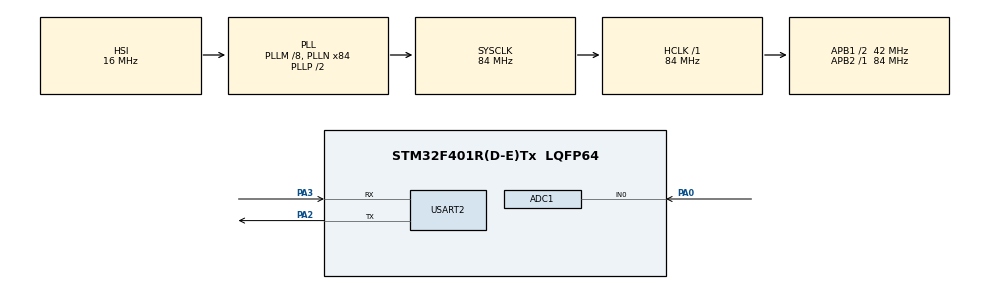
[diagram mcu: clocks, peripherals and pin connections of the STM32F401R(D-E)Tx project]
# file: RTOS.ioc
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ADC1.Channel-0\#ChannelRegularConversion=ADC_CHANNEL_0
ADC1.NbrOfConversionFlag=1
ADC1.Rank-0\#ChannelRegularConversion=1
ADC1.SamplingTime-0\#ChannelRegularConversion=ADC_SAMPLETIME_3CYCLES
ADC1.master=1
FREERTOS.Tasks01=defaultTask,0,128,StartDefaultTask,Default,NULL,Dynamic,NULL,NULL;ADCTask,0,128,StartADCTask,Default,NULL,Dynamic,NULL,NULL;UARTTask,0,128,StartUARTTask,Default,NULL,Dynamic,NULL,NULL
FREERTOS.configUSE_NEWLIB_REENTRANT=1
Mcu.Family=STM32F4
Mcu.Name=STM32F401R(D-E)Tx
Mcu.Package=LQFP64
NVIC.ADC_IRQn=true\:6\:0\:true\:false\:true\:true\:true\:true
NVIC.PriorityGroup=NVIC_PRIORITYGROUP_4
NVIC.TIM1_UP_TIM10_IRQn=true\:0\:0\:false\:false\:true\:false\:false\:true
NVIC.TIM3_IRQn=true\:5\:0\:false\:false\:true\:true\:true\:true
NVIC.TimeBase=TIM1_UP_TIM10_IRQn
NVIC.TimeBaseIP=TIM10
NVIC.USART2_IRQn=true\:7\:0\:true\:false\:true\:true\:true\:true
PA0-WKUP.Signal=ADCx_IN0
PA2.Mode=Asynchronous
PA2.Signal=USART2_TX
PA3.Mode=Asynchronous
PA3.Signal=USART2_RX
ProjectManager.HeapSize=0x3c00
ProjectManager.StackSize=0x3c00
ProjectManager.TargetToolchain=STM32CubeIDE
RCC.48MHZClocksFreq_Value=42000000
RCC.AHBFreq_Value=84000000
RCC.APB1CLKDivider=RCC_HCLK_DIV2
RCC.APB1Freq_Value=42000000
RCC.APB1TimFreq_Value=84000000
RCC.APB2Freq_Value=84000000
RCC.APB2TimFreq_Value=84000000
RCC.CortexFreq_Value=84000000
RCC.HCLKFreq_Value=84000000
RCC.HSE_VALUE=25000000
RCC.HSI_VALUE=16000000
RCC.LSE_VALUE=32768
RCC.PLLM=8
RCC.PLLN=84
RCC.SYSCLKFreq_VALUE=84000000
RCC.SYSCLKSource=RCC_SYSCLKSOURCE_PLLCLK
RCC.VCOOutputFreq_Value=168000000
SH.ADCx_IN0.0=ADC1_IN0,IN0
TIM3.AutoReloadPreload=TIM_AUTORELOAD_PRELOAD_ENABLE
TIM3.Period=1999
TIM3.Prescaler=42000
USART2.VirtualMode=VM_ASYNC
VP_FREERTOS_VS_CMSIS_V1.Mode=CMSIS_V1
VP_SYS_VS_tim10.Mode=TIM10
VP_TIM3_VS_ClockSourceINT.Mode=Internal
board=custom

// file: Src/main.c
/* USER CODE BEGIN Header */
/**
  ******************************************************************************
  * @file           : main.c
  * @brief          : Main program body
  ******************************************************************************
  * @attention
  *
  * <h2><center>&copy; Copyright (c) 2019 STMicroelectronics.
  * All rights reserved.</center></h2>
  *
  * This software component is licensed by ST under BSD 3-Clause license,
  * the "License"; You may not use this file except in compliance with the
  * License. You may obtain a copy of the License at:
  *                        opensource.org/licenses/BSD-3-Clause
  *
  ******************************************************************************
  */
/* USER CODE END Header */
#include "main.h"
#include "cmsis_os.h"

/* USER CODE BEGIN Includes */
#include <stdio.h>
#include <string.h>
/* USER CODE END Includes */

/* USER CODE BEGIN PD */
#define SIGNAL_TIM_INT 1
#define SIGNAL_ADC 2
#define SIGNAL_ADC_INT 4
#define SIGNAL_UART 8
#define SIGNAL_UART_INT 16
/* USER CODE END PD */

ADC_HandleTypeDef hadc1;

TIM_HandleTypeDef htim3;

UART_HandleTypeDef huart2;

osThreadId defaultTaskHandle;
osThreadId ADCTaskHandle;
osThreadId UARTTaskHandle;
/* USER CODE BEGIN PV */
uint8_t UARTBuf[16] = {'\0'};
/* USER CODE END PV */

void SystemClock_Config(void);
static void MX_GPIO_Init(void);
static void MX_ADC1_Init(void);
static void MX_TIM3_Init(void);
static void MX_USART2_UART_Init(void);
void StartDefaultTask(void const * argument);
void StartADCTask(void const * argument);
void StartUARTTask(void const * argument);

int main(void)
{

  /* MCU Configuration--------------------------------------------------------*/

  /* Reset of all peripherals, Initializes the Flash interface and the Systick. */
  HAL_Init();

  /* Configure the system clock */
  SystemClock_Config();

  /* Initialize all configured peripherals */
  MX_GPIO_Init();
  MX_ADC1_Init();
  MX_TIM3_Init();
  MX_USART2_UART_Init();

  /* Create the thread(s) */
  /* definition and creation of defaultTask */
  osThreadDef(defaultTask, StartDefaultTask, osPriorityNormal, 0, 128);
  defaultTaskHandle = osThreadCreate(osThread(defaultTask), NULL);

  /* definition and creation of ADCTask */
  osThreadDef(ADCTask, StartADCTask, osPriorityNormal, 0, 128);
  ADCTaskHandle = osThreadCreate(osThread(ADCTask), NULL);

  /* definition and creation of UARTTask */
  osThreadDef(UARTTask, StartUARTTask, osPriorityNormal, 0, 128);
  UARTTaskHandle = osThreadCreate(osThread(UARTTask), NULL);

  /* Start scheduler */
  osKernelStart();

  /* We should never get here as control is now taken by the scheduler */
  /* Infinite loop */
  while (1)
  {

  }
}

void SystemClock_Config(void)
{
  RCC_OscInitTypeDef RCC_OscInitStruct = {0};
  RCC_ClkInitTypeDef RCC_ClkInitStruct = {0};

  /** Configure the main internal regulator output voltage
  */
  __HAL_RCC_PWR_CLK_ENABLE();
  __HAL_PWR_VOLTAGESCALING_CONFIG(PWR_REGULATOR_VOLTAGE_SCALE2);
  /** Initializes the RCC Oscillators according to the specified parameters
  * in the RCC_OscInitTypeDef structure.
  */
  RCC_OscInitStruct.OscillatorType = RCC_OSCILLATORTYPE_HSI;
  RCC_OscInitStruct.HSIState = RCC_HSI_ON;
  RCC_OscInitStruct.HSICalibrationValue = RCC_HSICALIBRATION_DEFAULT;
  RCC_OscInitStruct.PLL.PLLState = RCC_PLL_ON;
  RCC_OscInitStruct.PLL.PLLSource = RCC_PLLSOURCE_HSI;
  RCC_OscInitStruct.PLL.PLLM = 8;
  RCC_OscInitStruct.PLL.PLLN = 84;
  RCC_OscInitStruct.PLL.PLLP = RCC_PLLP_DIV2;
  RCC_OscInitStruct.PLL.PLLQ = 4;
  if (HAL_RCC_OscConfig(&RCC_OscInitStruct) != HAL_OK)
  {
    Error_Handler();
  }
  /** Initializes the CPU, AHB and APB buses clocks
  */
  RCC_ClkInitStruct.ClockType = RCC_CLOCKTYPE_HCLK|RCC_CLOCKTYPE_SYSCLK
                              |RCC_CLOCKTYPE_PCLK1|RCC_CLOCKTYPE_PCLK2;
  RCC_ClkInitStruct.SYSCLKSource = RCC_SYSCLKSOURCE_PLLCLK;
  RCC_ClkInitStruct.AHBCLKDivider = RCC_SYSCLK_DIV1;
  RCC_ClkInitStruct.APB1CLKDivider = RCC_HCLK_DIV2;
  RCC_ClkInitStruct.APB2CLKDivider = RCC_HCLK_DIV1;

  if (HAL_RCC_ClockConfig(&RCC_ClkInitStruct, FLASH_LATENCY_2) != HAL_OK)
  {
    Error_Handler();
  }
}

static void MX_ADC1_Init(void)
{

  ADC_ChannelConfTypeDef sConfig = {0};

  /** Configure the global features of the ADC (Clock, Resolution, Data Alignment and number of conversion)
  */
  hadc1.Instance = ADC1;
  hadc1.Init.ClockPrescaler = ADC_CLOCK_SYNC_PCLK_DIV4;
  hadc1.Init.Resolution = ADC_RESOLUTION_12B;
  hadc1.Init.ScanConvMode = DISABLE;
  hadc1.Init.ContinuousConvMode = DISABLE;
  hadc1.Init.DiscontinuousConvMode = DISABLE;
  hadc1.Init.ExternalTrigConvEdge = ADC_EXTERNALTRIGCONVEDGE_NONE;
  hadc1.Init.ExternalTrigConv = ADC_SOFTWARE_START;
  hadc1.Init.DataAlign = ADC_DATAALIGN_RIGHT;
  hadc1.Init.NbrOfConversion = 1;
  hadc1.Init.DMAContinuousRequests = DISABLE;
  hadc1.Init.EOCSelection = ADC_EOC_SINGLE_CONV;
  if (HAL_ADC_Init(&hadc1) != HAL_OK)
  {
    Error_Handler();
  }
  /** Configure for the selected ADC regular channel its corresponding rank in the sequencer and its sample time.
  */
  sConfig.Channel = ADC_CHANNEL_0;
  sConfig.Rank = 1;
  sConfig.SamplingTime = ADC_SAMPLETIME_3CYCLES;
  if (HAL_ADC_ConfigChannel(&hadc1, &sConfig) != HAL_OK)
  {
    Error_Handler();
  }

}

static void MX_TIM3_Init(void)
{

  TIM_ClockConfigTypeDef sClockSourceConfig = {0};
  TIM_MasterConfigTypeDef sMasterConfig = {0};

  htim3.Instance = TIM3;
  htim3.Init.Prescaler = 42000;
  htim3.Init.CounterMode = TIM_COUNTERMODE_UP;
  htim3.Init.Period = 1999;
  htim3.Init.ClockDivision = TIM_CLOCKDIVISION_DIV1;
  htim3.Init.AutoReloadPreload = TIM_AUTORELOAD_PRELOAD_ENABLE;
  if (HAL_TIM_Base_Init(&htim3) != HAL_OK)
  {
    Error_Handler();
  }
  sClockSourceConfig.ClockSource = TIM_CLOCKSOURCE_INTERNAL;
  if (HAL_TIM_ConfigClockSource(&htim3, &sClockSourceConfig) != HAL_OK)
  {
    Error_Handler();
  }
  sMasterConfig.MasterOutputTrigger = TIM_TRGO_RESET;
  sMasterConfig.MasterSlaveMode = TIM_MASTERSLAVEMODE_DISABLE;
  if (HAL_TIMEx_MasterConfigSynchronization(&htim3, &sMasterConfig) != HAL_OK)
  {
    Error_Handler();
  }

}

static void MX_USART2_UART_Init(void)
{

  huart2.Instance = USART2;
  huart2.Init.BaudRate = 115200;
  huart2.Init.WordLength = UART_WORDLENGTH_8B;
  huart2.Init.StopBits = UART_STOPBITS_1;
  huart2.Init.Parity = UART_PARITY_NONE;
  huart2.Init.Mode = UART_MODE_TX_RX;
  huart2.Init.HwFlowCtl = UART_HWCONTROL_NONE;
  huart2.Init.OverSampling = UART_OVERSAMPLING_16;
  if (HAL_UART_Init(&huart2) != HAL_OK)
  {
    Error_Handler();
  }

}

static void MX_GPIO_Init(void)
{

  /* GPIO Ports Clock Enable */
  __HAL_RCC_GPIOA_CLK_ENABLE();

}

/* USER CODE BEGIN 4 */
void HAL_ADC_ConvCpltCallback(ADC_HandleTypeDef* hadc)
{
	if (hadc == &hadc1) {
		osSignalSet(ADCTaskHandle, SIGNAL_ADC_INT);
	}
}
void HAL_UART_TxCpltCallback(UART_HandleTypeDef *huart)
{
	if (huart == &huart2) {
		osSignalSet(UARTTaskHandle, SIGNAL_UART_INT);
	}
}
/* USER CODE END 4 */

void StartDefaultTask(void const * argument)
{
  /* USER CODE BEGIN 5 */
	HAL_TIM_Base_Start_IT(&htim3);
  /* Infinite loop */
  for(;;)
  {
	  osSignalWait(SIGNAL_TIM_INT, osWaitForever);
	  osSignalSet(ADCTaskHandle, SIGNAL_ADC);
  }
  /* USER CODE END 5 */
}

void StartADCTask(void const * argument)
{
  /* USER CODE BEGIN StartADCTask */
	uint32_t adcValue;
  /* Infinite loop */
  for(;;)
  {
	  osSignalWait(SIGNAL_ADC, osWaitForever);
	  HAL_ADC_Start_IT(&hadc1);
	  osSignalWait(SIGNAL_ADC_INT, osWaitForever);
	  adcValue = HAL_ADC_GetValue(&hadc1);
	  HAL_ADC_Stop_IT(&hadc1);
	  sprintf((char *)UARTBuf, "%ld\n", adcValue);
	  osSignalSet(UARTTaskHandle, SIGNAL_UART);
  }
  /* USER CODE END StartADCTask */
}

void StartUARTTask(void const * argument)
{
  /* USER CODE BEGIN StartUARTTask */
  /* Infinite loop */
  for(;;)
  {
	  osSignalWait(SIGNAL_UART, osWaitForever);
	  HAL_UART_Transmit_IT(&huart2, UARTBuf, strlen((const char *)UARTBuf));
	  osSignalWait(SIGNAL_UART_INT, osWaitForever);
  }
  /* USER CODE END StartUARTTask */
}

void HAL_TIM_PeriodElapsedCallback(TIM_HandleTypeDef *htim)
{
  /* USER CODE BEGIN Callback 0 */
  if (htim->Instance == TIM3) {
	  osSignalSet(defaultTaskHandle, SIGNAL_TIM_INT);
  }
  /* USER CODE END Callback 0 */
  if (htim->Instance == TIM10) {
    HAL_IncTick();
  }
}

void Error_Handler(void)
{
}

/************************ (C) COPYRIGHT STMicroelectronics *****END OF FILE****/

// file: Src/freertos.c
/* USER CODE BEGIN Header */
/**
  ******************************************************************************
  * File Name          : freertos.c
  * Description        : Code for freertos applications
  ******************************************************************************
  * @attention
  *
  * <h2><center>&copy; Copyright (c) 2019 STMicroelectronics.
  * All rights reserved.</center></h2>
  *
  * This software component is licensed by ST under Ultimate Liberty license
  * SLA0044, the "License"; You may not use this file except in compliance with
  * the License. You may obtain a copy of the License at:
  *                             www.st.com/SLA0044
  *
  ******************************************************************************
  */
/* USER CODE END Header */

#include "FreeRTOS.h"
#include "task.h"
#include "main.h"

/* GetIdleTaskMemory prototype (linked to static allocation support) */
void vApplicationGetIdleTaskMemory( StaticTask_t **ppxIdleTaskTCBBuffer, StackType_t **ppxIdleTaskStackBuffer, uint32_t *pulIdleTaskStackSize );

/* USER CODE BEGIN GET_IDLE_TASK_MEMORY */
static StaticTask_t xIdleTaskTCBBuffer;
static StackType_t xIdleStack[configMINIMAL_STACK_SIZE];

void vApplicationGetIdleTaskMemory( StaticTask_t **ppxIdleTaskTCBBuffer, StackType_t **ppxIdleTaskStackBuffer, uint32_t *pulIdleTaskStackSize )
{
  *ppxIdleTaskTCBBuffer = &xIdleTaskTCBBuffer;
  *ppxIdleTaskStackBuffer = &xIdleStack[0];
  *pulIdleTaskStackSize = configMINIMAL_STACK_SIZE;
  /* place for user code */
}
/* USER CODE END GET_IDLE_TASK_MEMORY */

/************************ (C) COPYRIGHT STMicroelectronics *****END OF FILE****/
